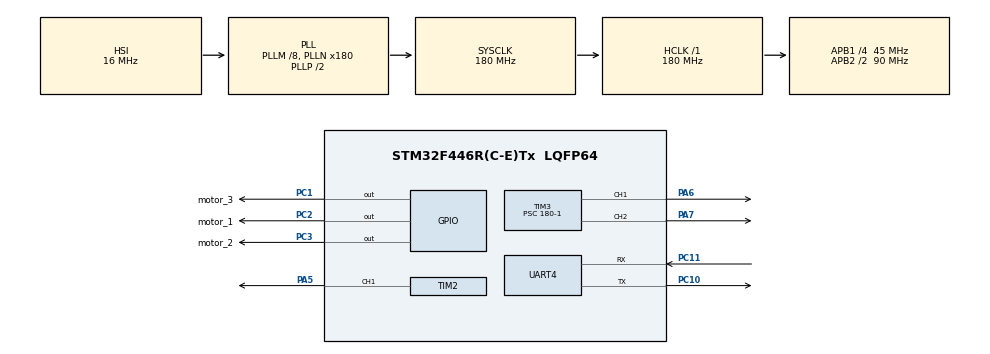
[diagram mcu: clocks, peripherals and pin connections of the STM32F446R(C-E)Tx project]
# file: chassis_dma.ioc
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Dma.Request0=UART4_RX
Dma.UART4_RX.0.Direction=DMA_PERIPH_TO_MEMORY
Dma.UART4_RX.0.FIFOMode=DMA_FIFOMODE_DISABLE
Dma.UART4_RX.0.Instance=DMA1_Stream2
Dma.UART4_RX.0.MemDataAlignment=DMA_MDATAALIGN_BYTE
Dma.UART4_RX.0.MemInc=DMA_MINC_ENABLE
Dma.UART4_RX.0.Mode=DMA_CIRCULAR
Dma.UART4_RX.0.PeriphDataAlignment=DMA_PDATAALIGN_BYTE
Dma.UART4_RX.0.PeriphInc=DMA_PINC_DISABLE
Dma.UART4_RX.0.Priority=DMA_PRIORITY_LOW
Mcu.Family=STM32F4
Mcu.Name=STM32F446R(C-E)Tx
Mcu.Package=LQFP64
NVIC.DMA1_Stream2_IRQn=true\:0\:0\:false\:false\:true\:false\:true\:true
NVIC.PriorityGroup=NVIC_PRIORITYGROUP_0
NVIC.UART4_IRQn=true\:0\:0\:false\:false\:true\:true\:true\:true
PA5.Signal=S_TIM2_CH1_ETR
PA6.Signal=S_TIM3_CH1
PA7.Signal=S_TIM3_CH2
PC1.GPIO_Label=motor_3
PC1.Signal=GPIO_Output
PC10.Mode=Asynchronous
PC10.Signal=UART4_TX
PC11.Mode=Asynchronous
PC11.Signal=UART4_RX
PC2.GPIO_Label=motor_1
PC2.Signal=GPIO_Output
PC3.GPIO_Label=motor_2
PC3.Signal=GPIO_Output
ProjectManager.HeapSize=0x200
ProjectManager.StackSize=0x400
ProjectManager.TargetToolchain=STM32CubeIDE
RCC.48MHZClocksFreq_Value=84000000
RCC.AHBFreq_Value=180000000
RCC.APB1CLKDivider=RCC_HCLK_DIV4
RCC.APB1Freq_Value=45000000
RCC.APB1TimFreq_Value=90000000
RCC.APB2CLKDivider=RCC_HCLK_DIV2
RCC.APB2Freq_Value=90000000
RCC.APB2TimFreq_Value=180000000
RCC.CortexFreq_Value=180000000
RCC.FLatency-AdvancedSettings=FLASH_LATENCY_5
RCC.HCLKFreq_Value=180000000
RCC.HSE_VALUE=8000000
RCC.HSI_VALUE=16000000
RCC.PLLM=8
RCC.PLLN=180
RCC.SYSCLKFreq_VALUE=180000000
RCC.SYSCLKSource=RCC_SYSCLKSOURCE_PLLCLK
RCC.USBFreq_Value=180000000
RCC.VCOOutputFreq_Value=360000000
SH.S_TIM2_CH1_ETR.0=TIM2_CH1,PWM Generation1 CH1
SH.S_TIM3_CH1.0=TIM3_CH1,PWM Generation1 CH1
SH.S_TIM3_CH2.0=TIM3_CH2,PWM Generation2 CH2
TIM1.Period=1000-1
TIM1.Prescaler=180-1
TIM2.Channel-PWM\ Generation1\ CH1=TIM_CHANNEL_1
TIM2.Period=1000-1
TIM2.Prescaler=180-1
TIM3.Channel-PWM\ Generation1\ CH1=TIM_CHANNEL_1
TIM3.Channel-PWM\ Generation2\ CH2=TIM_CHANNEL_2
TIM3.Period=1000-1
TIM3.Prescaler=180-1
TIM5.Period=1000-1
TIM5.Prescaler=180-1
UART4.VirtualMode=Asynchronous
VP_TIM1_VS_ClockSourceINT.Mode=Internal
VP_TIM2_VS_ClockSourceINT.Mode=Internal
VP_TIM3_VS_ClockSourceINT.Mode=Internal
VP_TIM5_VS_ClockSourceINT.Mode=Internal
board=NUCLEO-F446RE

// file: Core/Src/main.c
/* USER CODE BEGIN Header */
/**
  ******************************************************************************
  * @file           : main.c
  * @brief          : Main program body
  ******************************************************************************
  * @attention
  *
  * Copyright (c) 2025 STMicroelectronics.
  * All rights reserved.
  *
  * This software is licensed under terms that can be found in the LICENSE file
  * in the root directory of this software component.
  * If no LICENSE file comes with this software, it is provided AS-IS.
  *
  ******************************************************************************
  */
/* USER CODE END Header */
#include "main.h"
#include "stdio.h"

#include "encoder_position.h"

TIM_HandleTypeDef htim1;
TIM_HandleTypeDef htim2;
TIM_HandleTypeDef htim3;
TIM_HandleTypeDef htim5;

UART_HandleTypeDef huart4;
DMA_HandleTypeDef hdma_uart4_rx;

void SystemClock_Config(void);
static void MX_GPIO_Init(void);
static void MX_DMA_Init(void);
static void MX_TIM2_Init(void);
static void MX_TIM3_Init(void);
static void MX_UART4_Init(void);
static void MX_TIM5_Init(void);
static void MX_TIM1_Init(void);

/* USER CODE BEGIN 0 */
uint8_t rxbuff[16];

int32_t lx, ly, rx, ry, cro, squ, tri, cir, up, down, left, right, ll1, rr1, ll2, rr2;

void HAL_UART_RxCpltCallback(UART_HandleTypeDef *huart){

	 HAL_UART_Receive_DMA(&huart4, rxbuff, 64);
}

/* USER CODE END 0 */

int main(void)
{

  /* MCU Configuration--------------------------------------------------------*/

  /* Reset of all peripherals, Initializes the Flash interface and the Systick. */
  HAL_Init();

  /* Configure the system clock */
  SystemClock_Config();

  /* Initialize all configured peripherals */
  MX_GPIO_Init();
  MX_DMA_Init();
  MX_TIM2_Init();
  MX_TIM3_Init();
  MX_UART4_Init();
  MX_TIM5_Init();
  MX_TIM1_Init();
  /* USER CODE BEGIN 2 */
  HAL_UART_Receive_DMA(&huart4, rxbuff, 64);
  /* USER CODE END 2 */

  /* Infinite loop */
  while (1)
  {
		lx = (rxbuff[0] & 0x80) ? (int32_t)rxbuff[0] - 256 : (int32_t)rxbuff[0];

	    ly = (rxbuff[1] & 0x80) ? (int32_t)rxbuff[1] - 256 : (int32_t)rxbuff[1];

	    rx = (rxbuff[2] & 0x80) ? (int32_t)rxbuff[2] - 256 : (int32_t)rxbuff[2];

	    ry = (rxbuff[3] & 0x80) ? (int32_t)rxbuff[3] - 256 : (int32_t)rxbuff[3];

	    cro= (rxbuff[4] & 0x80) ? (int32_t)rxbuff[4] - 256 : (int32_t)rxbuff[4];
	//
	    squ= (rxbuff[5] & 0x80) ? (int32_t)rxbuff[5] - 256 : (int32_t)rxbuff[5];
	  printf("Received Integers:\n");

	 	   printf("lx: %ld ", lx);

	 	   printf("ly: %ld ", ly);

	 	   printf("rx: %ld ", rx);

	 	   printf("ry: %ld \n", ry);

	 	//
	 	   printf("cro: %ld\n", cro);
	 	//
	 	   printf("squ: %ld\n", squ);
  }
}

void SystemClock_Config(void)
{
  RCC_OscInitTypeDef RCC_OscInitStruct = {0};
  RCC_ClkInitTypeDef RCC_ClkInitStruct = {0};

  /** Configure the main internal regulator output voltage
  */
  __HAL_RCC_PWR_CLK_ENABLE();
  __HAL_PWR_VOLTAGESCALING_CONFIG(PWR_REGULATOR_VOLTAGE_SCALE1);

  /** Initializes the RCC Oscillators according to the specified parameters
  * in the RCC_OscInitTypeDef structure.
  */
  RCC_OscInitStruct.OscillatorType = RCC_OSCILLATORTYPE_HSI;
  RCC_OscInitStruct.HSIState = RCC_HSI_ON;
  RCC_OscInitStruct.HSICalibrationValue = RCC_HSICALIBRATION_DEFAULT;
  RCC_OscInitStruct.PLL.PLLState = RCC_PLL_ON;
  RCC_OscInitStruct.PLL.PLLSource = RCC_PLLSOURCE_HSI;
  RCC_OscInitStruct.PLL.PLLM = 8;
  RCC_OscInitStruct.PLL.PLLN = 180;
  RCC_OscInitStruct.PLL.PLLP = RCC_PLLP_DIV2;
  RCC_OscInitStruct.PLL.PLLQ = 2;
  RCC_OscInitStruct.PLL.PLLR = 2;
  if (HAL_RCC_OscConfig(&RCC_OscInitStruct) != HAL_OK)
  {
    Error_Handler();
  }

  /** Activate the Over-Drive mode
  */
  if (HAL_PWREx_EnableOverDrive() != HAL_OK)
  {
    Error_Handler();
  }

  /** Initializes the CPU, AHB and APB buses clocks
  */
  RCC_ClkInitStruct.ClockType = RCC_CLOCKTYPE_HCLK|RCC_CLOCKTYPE_SYSCLK
                              |RCC_CLOCKTYPE_PCLK1|RCC_CLOCKTYPE_PCLK2;
  RCC_ClkInitStruct.SYSCLKSource = RCC_SYSCLKSOURCE_PLLCLK;
  RCC_ClkInitStruct.AHBCLKDivider = RCC_SYSCLK_DIV1;
  RCC_ClkInitStruct.APB1CLKDivider = RCC_HCLK_DIV4;
  RCC_ClkInitStruct.APB2CLKDivider = RCC_HCLK_DIV2;

  if (HAL_RCC_ClockConfig(&RCC_ClkInitStruct, FLASH_LATENCY_5) != HAL_OK)
  {
    Error_Handler();
  }
}

static void MX_TIM1_Init(void)
{

  TIM_ClockConfigTypeDef sClockSourceConfig = {0};
  TIM_MasterConfigTypeDef sMasterConfig = {0};

  htim1.Instance = TIM1;
  htim1.Init.Prescaler = 180-1;
  htim1.Init.CounterMode = TIM_COUNTERMODE_UP;
  htim1.Init.Period = 1000-1;
  htim1.Init.ClockDivision = TIM_CLOCKDIVISION_DIV1;
  htim1.Init.RepetitionCounter = 0;
  htim1.Init.AutoReloadPreload = TIM_AUTORELOAD_PRELOAD_DISABLE;
  if (HAL_TIM_Base_Init(&htim1) != HAL_OK)
  {
    Error_Handler();
  }
  sClockSourceConfig.ClockSource = TIM_CLOCKSOURCE_INTERNAL;
  if (HAL_TIM_ConfigClockSource(&htim1, &sClockSourceConfig) != HAL_OK)
  {
    Error_Handler();
  }
  sMasterConfig.MasterOutputTrigger = TIM_TRGO_RESET;
  sMasterConfig.MasterSlaveMode = TIM_MASTERSLAVEMODE_DISABLE;
  if (HAL_TIMEx_MasterConfigSynchronization(&htim1, &sMasterConfig) != HAL_OK)
  {
    Error_Handler();
  }

}

static void MX_TIM2_Init(void)
{

  TIM_ClockConfigTypeDef sClockSourceConfig = {0};
  TIM_MasterConfigTypeDef sMasterConfig = {0};
  TIM_OC_InitTypeDef sConfigOC = {0};

  htim2.Instance = TIM2;
  htim2.Init.Prescaler = 180-1;
  htim2.Init.CounterMode = TIM_COUNTERMODE_UP;
  htim2.Init.Period = 1000-1;
  htim2.Init.ClockDivision = TIM_CLOCKDIVISION_DIV1;
  htim2.Init.AutoReloadPreload = TIM_AUTORELOAD_PRELOAD_DISABLE;
  if (HAL_TIM_Base_Init(&htim2) != HAL_OK)
  {
    Error_Handler();
  }
  sClockSourceConfig.ClockSource = TIM_CLOCKSOURCE_INTERNAL;
  if (HAL_TIM_ConfigClockSource(&htim2, &sClockSourceConfig) != HAL_OK)
  {
    Error_Handler();
  }
  if (HAL_TIM_PWM_Init(&htim2) != HAL_OK)
  {
    Error_Handler();
  }
  sMasterConfig.MasterOutputTrigger = TIM_TRGO_RESET;
  sMasterConfig.MasterSlaveMode = TIM_MASTERSLAVEMODE_DISABLE;
  if (HAL_TIMEx_MasterConfigSynchronization(&htim2, &sMasterConfig) != HAL_OK)
  {
    Error_Handler();
  }
  sConfigOC.OCMode = TIM_OCMODE_PWM1;
  sConfigOC.Pulse = 0;
  sConfigOC.OCPolarity = TIM_OCPOLARITY_HIGH;
  sConfigOC.OCFastMode = TIM_OCFAST_DISABLE;
  if (HAL_TIM_PWM_ConfigChannel(&htim2, &sConfigOC, TIM_CHANNEL_1) != HAL_OK)
  {
    Error_Handler();
  }
  HAL_TIM_MspPostInit(&htim2);

}

static void MX_TIM3_Init(void)
{

  TIM_ClockConfigTypeDef sClockSourceConfig = {0};
  TIM_MasterConfigTypeDef sMasterConfig = {0};
  TIM_OC_InitTypeDef sConfigOC = {0};

  htim3.Instance = TIM3;
  htim3.Init.Prescaler = 180-1;
  htim3.Init.CounterMode = TIM_COUNTERMODE_UP;
  htim3.Init.Period = 1000-1;
  htim3.Init.ClockDivision = TIM_CLOCKDIVISION_DIV1;
  htim3.Init.AutoReloadPreload = TIM_AUTORELOAD_PRELOAD_DISABLE;
  if (HAL_TIM_Base_Init(&htim3) != HAL_OK)
  {
    Error_Handler();
  }
  sClockSourceConfig.ClockSource = TIM_CLOCKSOURCE_INTERNAL;
  if (HAL_TIM_ConfigClockSource(&htim3, &sClockSourceConfig) != HAL_OK)
  {
    Error_Handler();
  }
  if (HAL_TIM_PWM_Init(&htim3) != HAL_OK)
  {
    Error_Handler();
  }
  sMasterConfig.MasterOutputTrigger = TIM_TRGO_RESET;
  sMasterConfig.MasterSlaveMode = TIM_MASTERSLAVEMODE_DISABLE;
  if (HAL_TIMEx_MasterConfigSynchronization(&htim3, &sMasterConfig) != HAL_OK)
  {
    Error_Handler();
  }
  sConfigOC.OCMode = TIM_OCMODE_PWM1;
  sConfigOC.Pulse = 0;
  sConfigOC.OCPolarity = TIM_OCPOLARITY_HIGH;
  sConfigOC.OCFastMode = TIM_OCFAST_DISABLE;
  if (HAL_TIM_PWM_ConfigChannel(&htim3, &sConfigOC, TIM_CHANNEL_1) != HAL_OK)
  {
    Error_Handler();
  }
  if (HAL_TIM_PWM_ConfigChannel(&htim3, &sConfigOC, TIM_CHANNEL_2) != HAL_OK)
  {
    Error_Handler();
  }
  HAL_TIM_MspPostInit(&htim3);

}

static void MX_TIM5_Init(void)
{

  TIM_ClockConfigTypeDef sClockSourceConfig = {0};
  TIM_MasterConfigTypeDef sMasterConfig = {0};

  htim5.Instance = TIM5;
  htim5.Init.Prescaler = 180-1;
  htim5.Init.CounterMode = TIM_COUNTERMODE_UP;
  htim5.Init.Period = 1000-1;
  htim5.Init.ClockDivision = TIM_CLOCKDIVISION_DIV1;
  htim5.Init.AutoReloadPreload = TIM_AUTORELOAD_PRELOAD_DISABLE;
  if (HAL_TIM_Base_Init(&htim5) != HAL_OK)
  {
    Error_Handler();
  }
  sClockSourceConfig.ClockSource = TIM_CLOCKSOURCE_INTERNAL;
  if (HAL_TIM_ConfigClockSource(&htim5, &sClockSourceConfig) != HAL_OK)
  {
    Error_Handler();
  }
  sMasterConfig.MasterOutputTrigger = TIM_TRGO_RESET;
  sMasterConfig.MasterSlaveMode = TIM_MASTERSLAVEMODE_DISABLE;
  if (HAL_TIMEx_MasterConfigSynchronization(&htim5, &sMasterConfig) != HAL_OK)
  {
    Error_Handler();
  }

}

static void MX_UART4_Init(void)
{

  huart4.Instance = UART4;
  huart4.Init.BaudRate = 115200;
  huart4.Init.WordLength = UART_WORDLENGTH_8B;
  huart4.Init.StopBits = UART_STOPBITS_1;
  huart4.Init.Parity = UART_PARITY_NONE;
  huart4.Init.Mode = UART_MODE_TX_RX;
  huart4.Init.HwFlowCtl = UART_HWCONTROL_NONE;
  huart4.Init.OverSampling = UART_OVERSAMPLING_16;
  if (HAL_UART_Init(&huart4) != HAL_OK)
  {
    Error_Handler();
  }

}

static void MX_DMA_Init(void)
{

  /* DMA controller clock enable */
  __HAL_RCC_DMA1_CLK_ENABLE();

  /* DMA interrupt init */
  /* DMA1_Stream2_IRQn interrupt configuration */
  HAL_NVIC_SetPriority(DMA1_Stream2_IRQn, 0, 0);
  HAL_NVIC_EnableIRQ(DMA1_Stream2_IRQn);

}

static void MX_GPIO_Init(void)
{
  GPIO_InitTypeDef GPIO_InitStruct = {0};

  /* GPIO Ports Clock Enable */
  __HAL_RCC_GPIOC_CLK_ENABLE();
  __HAL_RCC_GPIOA_CLK_ENABLE();

  /*Configure GPIO pin Output Level */
  HAL_GPIO_WritePin(GPIOC, motor_3_Pin|motor_1_Pin|motor_2_Pin, GPIO_PIN_RESET);

  /*Configure GPIO pins : motor_3_Pin motor_1_Pin motor_2_Pin */
  GPIO_InitStruct.Pin = motor_3_Pin|motor_1_Pin|motor_2_Pin;
  GPIO_InitStruct.Mode = GPIO_MODE_OUTPUT_PP;
  GPIO_InitStruct.Pull = GPIO_NOPULL;
  GPIO_InitStruct.Speed = GPIO_SPEED_FREQ_LOW;
  HAL_GPIO_Init(GPIOC, &GPIO_InitStruct);

}

void Error_Handler(void)
{
  __disable_irq();
  while (1)
  {
  }
}
